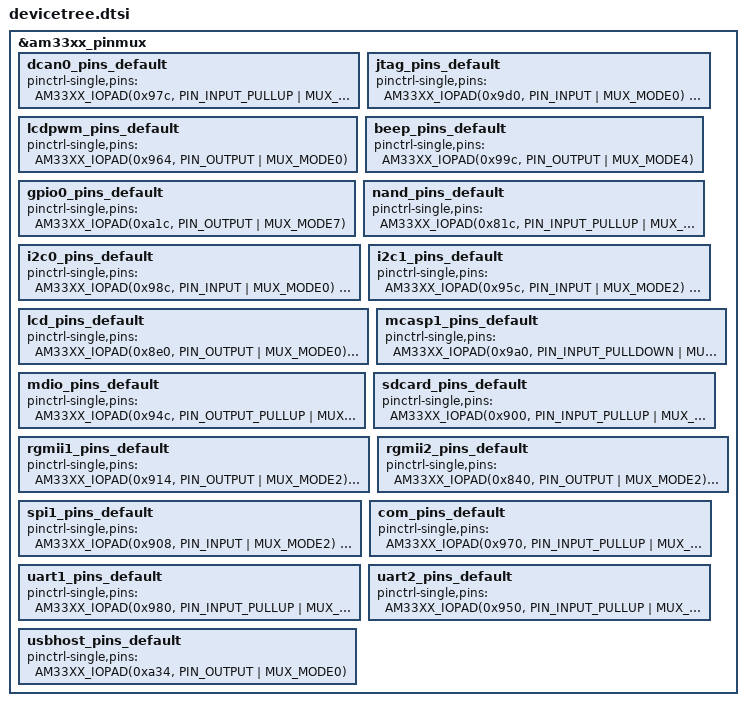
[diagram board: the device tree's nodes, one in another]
/* This file was auto-generated by TI PinMux on 2021/3/4 at 下午6:34:33. */
/* This file should only be used as a reference. Some pins/peripherals, */
/* depending on your use case, may need additional configuration. */

/* Some or all the pins from the following groups are not used by device tree 
   adc
   ddr3l
   otg
   usbhost
*/

&am33xx_pinmux {
	dcan0_pins_default: dcan0_pins_default {
		pinctrl-single,pins = <
			AM33XX_IOPAD(0x97c, PIN_INPUT_PULLUP | MUX_MODE2) /* (D17) uart1_rtsn.dcan0_rx */
			AM33XX_IOPAD(0x978, PIN_OUTPUT | MUX_MODE2) /* (D18) uart1_ctsn.dcan0_tx */
		>;
	};

	jtag_pins_default: jtag_pins_default {
		pinctrl-single,pins = <
			AM33XX_IOPAD(0x9d0, PIN_INPUT | MUX_MODE0) /* (C11) TMS.TMS */
			AM33XX_IOPAD(0x9d4, PIN_INPUT | MUX_MODE0) /* (B11) TDI.TDI */
			AM33XX_IOPAD(0x9d8, PIN_OUTPUT | MUX_MODE0) /* (A11) TDO.TDO */
			AM33XX_IOPAD(0x9dc, PIN_INPUT | MUX_MODE0) /* (A12) TCK.TCK */
			AM33XX_IOPAD(0x9e0, PIN_INPUT | MUX_MODE0) /* (B10) nTRST.nTRST */
			AM33XX_IOPAD(0x9e4, PIN_INPUT | MUX_MODE0) /* (C14) EMU0.EMU0 */
			AM33XX_IOPAD(0x9e8, PIN_INPUT | MUX_MODE0) /* (B14) EMU1.EMU1 */
		>;
	};

	lcdpwm_pins_default: lcdpwm_pins_default {
		pinctrl-single,pins = <
			AM33XX_IOPAD(0x964, PIN_OUTPUT | MUX_MODE0) /* (C18) eCAP0_in_PWM0_out.eCAP0_in_PWM0_out */
		>;
	};

	beep_pins_default: beep_pins_default {
		pinctrl-single,pins = <
			AM33XX_IOPAD(0x99c, PIN_OUTPUT | MUX_MODE4) /* (C12) mcasp0_ahclkr.eCAP2_in_PWM2_out */
		>;
	};

	gpio0_pins_default: gpio0_pins_default {
		pinctrl-single,pins = <
			AM33XX_IOPAD(0xa1c, PIN_OUTPUT | MUX_MODE7) /* (F16) USB0_DRVVBUS.gpio0[18] */
		>;
	};

	nand_pins_default: nand_pins_default {
		pinctrl-single,pins = <
			AM33XX_IOPAD(0x81c, PIN_INPUT_PULLUP | MUX_MODE0) /* (T9) gpmc_ad7.gpmc_ad7 */
			AM33XX_IOPAD(0x818, PIN_INPUT_PULLUP | MUX_MODE0) /* (R9) gpmc_ad6.gpmc_ad6 */
			AM33XX_IOPAD(0x814, PIN_INPUT_PULLUP | MUX_MODE0) /* (V8) gpmc_ad5.gpmc_ad5 */
			AM33XX_IOPAD(0x810, PIN_INPUT_PULLUP | MUX_MODE0) /* (U8) gpmc_ad4.gpmc_ad4 */
			AM33XX_IOPAD(0x80c, PIN_INPUT_PULLUP | MUX_MODE0) /* (T8) gpmc_ad3.gpmc_ad3 */
			AM33XX_IOPAD(0x808, PIN_INPUT_PULLUP | MUX_MODE0) /* (R8) gpmc_ad2.gpmc_ad2 */
			AM33XX_IOPAD(0x804, PIN_INPUT_PULLUP | MUX_MODE0) /* (V7) gpmc_ad1.gpmc_ad1 */
			AM33XX_IOPAD(0x800, PIN_INPUT_PULLUP | MUX_MODE0) /* (U7) gpmc_ad0.gpmc_ad0 */
			AM33XX_IOPAD(0x870, PIN_INPUT_PULLUP | MUX_MODE0) /* (T17) gpmc_wait0.gpmc_wait0 */
			AM33XX_IOPAD(0x87c, PIN_OUTPUT | MUX_MODE0) /* (V6) gpmc_csn0.gpmc_csn0 */
			AM33XX_IOPAD(0x890, PIN_OUTPUT | MUX_MODE0) /* (R7) gpmc_advn_ale.gpmc_advn_ale */
			AM33XX_IOPAD(0x894, PIN_OUTPUT | MUX_MODE0) /* (T7) gpmc_oen_ren.gpmc_oen_ren */
			AM33XX_IOPAD(0x898, PIN_OUTPUT | MUX_MODE0) /* (U6) gpmc_wen.gpmc_wen */
			AM33XX_IOPAD(0x89c, PIN_OUTPUT | MUX_MODE0) /* (T6) gpmc_be0n_cle.gpmc_be0n_cle */
		>;
	};

	i2c0_pins_default: i2c0_pins_default {
		pinctrl-single,pins = <
			AM33XX_IOPAD(0x98c, PIN_INPUT | MUX_MODE0) /* (C16) I2C0_SCL.I2C0_SCL */
			AM33XX_IOPAD(0x988, PIN_INPUT | MUX_MODE0) /* (C17) I2C0_SDA.I2C0_SDA */
		>;
	};

	i2c1_pins_default: i2c1_pins_default {
		pinctrl-single,pins = <
			AM33XX_IOPAD(0x95c, PIN_INPUT | MUX_MODE2) /* (A16) spi0_cs0.I2C1_SCL */
			AM33XX_IOPAD(0x958, PIN_INPUT | MUX_MODE2) /* (B16) spi0_d1.I2C1_SDA */
		>;
	};

	lcd_pins_default: lcd_pins_default {
		pinctrl-single,pins = <
			AM33XX_IOPAD(0x8e0, PIN_OUTPUT | MUX_MODE0) /* (U5) lcd_vsync.lcd_vsync */
			AM33XX_IOPAD(0x8e4, PIN_OUTPUT | MUX_MODE0) /* (R5) lcd_hsync.lcd_hsync */
			AM33XX_IOPAD(0x8e8, PIN_OUTPUT | MUX_MODE0) /* (V5) lcd_pclk.lcd_pclk */
			AM33XX_IOPAD(0x8ec, PIN_OUTPUT | MUX_MODE0) /* (R6) lcd_ac_bias_en.lcd_ac_bias_en */
			AM33XX_IOPAD(0x8a0, PIN_OUTPUT | MUX_MODE0) /* (R1) lcd_data0.lcd_data0 */
			AM33XX_IOPAD(0x8a4, PIN_OUTPUT | MUX_MODE0) /* (R2) lcd_data1.lcd_data1 */
			AM33XX_IOPAD(0x8a8, PIN_OUTPUT | MUX_MODE0) /* (R3) lcd_data2.lcd_data2 */
			AM33XX_IOPAD(0x8ac, PIN_OUTPUT | MUX_MODE0) /* (R4) lcd_data3.lcd_data3 */
			AM33XX_IOPAD(0x8b0, PIN_OUTPUT | MUX_MODE0) /* (T1) lcd_data4.lcd_data4 */
			AM33XX_IOPAD(0x8b4, PIN_OUTPUT | MUX_MODE0) /* (T2) lcd_data5.lcd_data5 */
			AM33XX_IOPAD(0x8b8, PIN_OUTPUT | MUX_MODE0) /* (T3) lcd_data6.lcd_data6 */
			AM33XX_IOPAD(0x8bc, PIN_OUTPUT | MUX_MODE0) /* (T4) lcd_data7.lcd_data7 */
			AM33XX_IOPAD(0x8c0, PIN_OUTPUT | MUX_MODE0) /* (U1) lcd_data8.lcd_data8 */
			AM33XX_IOPAD(0x8c4, PIN_OUTPUT | MUX_MODE0) /* (U2) lcd_data9.lcd_data9 */
			AM33XX_IOPAD(0x8c8, PIN_OUTPUT | MUX_MODE0) /* (U3) lcd_data10.lcd_data10 */
			AM33XX_IOPAD(0x8cc, PIN_OUTPUT | MUX_MODE0) /* (U4) lcd_data11.lcd_data11 */
			AM33XX_IOPAD(0x8d0, PIN_OUTPUT | MUX_MODE0) /* (V2) lcd_data12.lcd_data12 */
			AM33XX_IOPAD(0x8d4, PIN_OUTPUT | MUX_MODE0) /* (V3) lcd_data13.lcd_data13 */
			AM33XX_IOPAD(0x8d8, PIN_OUTPUT | MUX_MODE0) /* (V4) lcd_data14.lcd_data14 */
			AM33XX_IOPAD(0x8dc, PIN_OUTPUT | MUX_MODE0) /* (T5) lcd_data15.lcd_data15 */
			AM33XX_IOPAD(0x83c, PIN_OUTPUT | MUX_MODE1) /* (U13) gpmc_ad15.lcd_data16 */
			AM33XX_IOPAD(0x838, PIN_OUTPUT | MUX_MODE1) /* (V13) gpmc_ad14.lcd_data17 */
			AM33XX_IOPAD(0x834, PIN_OUTPUT | MUX_MODE1) /* (R12) gpmc_ad13.lcd_data18 */
			AM33XX_IOPAD(0x830, PIN_OUTPUT | MUX_MODE1) /* (T12) gpmc_ad12.lcd_data19 */
			AM33XX_IOPAD(0x82c, PIN_OUTPUT | MUX_MODE1) /* (U12) gpmc_ad11.lcd_data20 */
			AM33XX_IOPAD(0x828, PIN_OUTPUT | MUX_MODE1) /* (T11) gpmc_ad10.lcd_data21 */
			AM33XX_IOPAD(0x824, PIN_OUTPUT | MUX_MODE1) /* (T10) gpmc_ad9.lcd_data22 */
			AM33XX_IOPAD(0x820, PIN_OUTPUT | MUX_MODE1) /* (U10) gpmc_ad8.lcd_data23 */
		>;
	};

	mcasp1_pins_default: mcasp1_pins_default {
		pinctrl-single,pins = <
			AM33XX_IOPAD(0x9a0, PIN_INPUT_PULLDOWN | MUX_MODE3) /* (B12) mcasp0_aclkr.mcasp1_aclkx */
			AM33XX_IOPAD(0x9a4, PIN_INPUT_PULLDOWN | MUX_MODE3) /* (C13) mcasp0_fsr.mcasp1_fsx */
			AM33XX_IOPAD(0x9a8, PIN_OUTPUT_PULLDOWN | MUX_MODE3) /* (D13) mcasp0_axr1.mcasp1_axr0 */
			AM33XX_IOPAD(0x9ac, PIN_OUTPUT_PULLDOWN | MUX_MODE3) /* (A14) mcasp0_ahclkx.mcasp1_axr1 */
		>;
	};

	mdio_pins_default: mdio_pins_default {
		pinctrl-single,pins = <
			AM33XX_IOPAD(0x94c, PIN_OUTPUT_PULLUP | MUX_MODE0) /* (M18) mdio_clk.mdio_clk */
			AM33XX_IOPAD(0x948, PIN_INPUT_PULLUP | MUX_MODE0) /* (M17) mdio_data.mdio_data */
		>;
	};

	sdcard_pins_default: sdcard_pins_default {
		pinctrl-single,pins = <
			AM33XX_IOPAD(0x900, PIN_INPUT_PULLUP | MUX_MODE0) /* (G17) mmc0_clk.mmc0_clk */
			AM33XX_IOPAD(0x904, PIN_INPUT_PULLUP | MUX_MODE0) /* (G18) mmc0_cmd.mmc0_cmd */
			AM33XX_IOPAD(0x8fc, PIN_INPUT_PULLUP | MUX_MODE0) /* (G16) mmc0_dat0.mmc0_dat0 */
			AM33XX_IOPAD(0x8f8, PIN_INPUT_PULLUP | MUX_MODE0) /* (G15) mmc0_dat1.mmc0_dat1 */
			AM33XX_IOPAD(0x8f4, PIN_INPUT_PULLUP | MUX_MODE0) /* (F18) mmc0_dat2.mmc0_dat2 */
			AM33XX_IOPAD(0x8f0, PIN_INPUT_PULLUP | MUX_MODE0) /* (F17) mmc0_dat3.mmc0_dat3 */
			AM33XX_IOPAD(0x960, PIN_INPUT_PULLUP | MUX_MODE5) /* (C15) spi0_cs1.mmc0_sdcd */
		>;
	};

	rgmii1_pins_default: rgmii1_pins_default {
		pinctrl-single,pins = <
			AM33XX_IOPAD(0x914, PIN_OUTPUT | MUX_MODE2) /* (J16) gmii1_txen.rgmii1_tctl */
			AM33XX_IOPAD(0x918, PIN_INPUT_PULLDOWN | MUX_MODE2) /* (J17) gmii1_rxdv.rgmii1_rctl */
			AM33XX_IOPAD(0x92c, PIN_OUTPUT | MUX_MODE2) /* (K18) gmii1_txclk.rgmii1_tclk */
			AM33XX_IOPAD(0x930, PIN_INPUT_PULLDOWN | MUX_MODE2) /* (L18) gmii1_rxclk.rgmii1_rclk */
			AM33XX_IOPAD(0x928, PIN_OUTPUT | MUX_MODE2) /* (K17) gmii1_txd0.rgmii1_td0 */
			AM33XX_IOPAD(0x924, PIN_OUTPUT | MUX_MODE2) /* (K16) gmii1_txd1.rgmii1_td1 */
			AM33XX_IOPAD(0x920, PIN_OUTPUT | MUX_MODE2) /* (K15) gmii1_txd2.rgmii1_td2 */
			AM33XX_IOPAD(0x91c, PIN_OUTPUT | MUX_MODE2) /* (J18) gmii1_txd3.rgmii1_td3 */
			AM33XX_IOPAD(0x940, PIN_INPUT_PULLDOWN | MUX_MODE2) /* (M16) gmii1_rxd0.rgmii1_rd0 */
			AM33XX_IOPAD(0x93c, PIN_INPUT_PULLDOWN | MUX_MODE2) /* (L15) gmii1_rxd1.rgmii1_rd1 */
			AM33XX_IOPAD(0x938, PIN_INPUT_PULLDOWN | MUX_MODE2) /* (L16) gmii1_rxd2.rgmii1_rd2 */
			AM33XX_IOPAD(0x934, PIN_INPUT_PULLDOWN | MUX_MODE2) /* (L17) gmii1_rxd3.rgmii1_rd3 */
		>;
	};

	rgmii2_pins_default: rgmii2_pins_default {
		pinctrl-single,pins = <
			AM33XX_IOPAD(0x840, PIN_OUTPUT | MUX_MODE2) /* (R13) gpmc_a0.rgmii2_tctl */
			AM33XX_IOPAD(0x844, PIN_INPUT_PULLDOWN | MUX_MODE2) /* (V14) gpmc_a1.rgmii2_rctl */
			AM33XX_IOPAD(0x858, PIN_OUTPUT | MUX_MODE2) /* (U15) gpmc_a6.rgmii2_tclk */
			AM33XX_IOPAD(0x85c, PIN_INPUT_PULLDOWN | MUX_MODE2) /* (T15) gpmc_a7.rgmii2_rclk */
			AM33XX_IOPAD(0x854, PIN_OUTPUT | MUX_MODE2) /* (V15) gpmc_a5.rgmii2_td0 */
			AM33XX_IOPAD(0x850, PIN_OUTPUT | MUX_MODE2) /* (R14) gpmc_a4.rgmii2_td1 */
			AM33XX_IOPAD(0x84c, PIN_OUTPUT | MUX_MODE2) /* (T14) gpmc_a3.rgmii2_td2 */
			AM33XX_IOPAD(0x848, PIN_OUTPUT | MUX_MODE2) /* (U14) gpmc_a2.rgmii2_td3 */
			AM33XX_IOPAD(0x86c, PIN_INPUT_PULLDOWN | MUX_MODE2) /* (V17) gpmc_a11.rgmii2_rd0 */
			AM33XX_IOPAD(0x868, PIN_INPUT_PULLDOWN | MUX_MODE2) /* (T16) gpmc_a10.rgmii2_rd1 */
			AM33XX_IOPAD(0x864, PIN_INPUT_PULLDOWN | MUX_MODE2) /* (U16) gpmc_a9.rgmii2_rd2 */
			AM33XX_IOPAD(0x860, PIN_INPUT_PULLDOWN | MUX_MODE2) /* (V16) gpmc_a8.rgmii2_rd3 */
		>;
	};

	spi1_pins_default: spi1_pins_default {
		pinctrl-single,pins = <
			AM33XX_IOPAD(0x908, PIN_INPUT | MUX_MODE2) /* (H16) gmii1_col.spi1_sclk */
			AM33XX_IOPAD(0x90c, PIN_INPUT_PULLUP | MUX_MODE2) /* (H17) gmii1_crs.spi1_d0 */
			AM33XX_IOPAD(0x910, PIN_INPUT | MUX_MODE2) /* (J15) gmii1_rxer.spi1_d1 */
			AM33XX_IOPAD(0x944, PIN_INPUT_PULLUP | MUX_MODE2) /* (H18) rmii1_refclk.spi1_cs0 */
		>;
	};

	com_pins_default: com_pins_default {
		pinctrl-single,pins = <
			AM33XX_IOPAD(0x970, PIN_INPUT_PULLUP | MUX_MODE0) /* (E15) uart0_rxd.uart0_rxd */
			AM33XX_IOPAD(0x974, PIN_OUTPUT | MUX_MODE0) /* (E16) uart0_txd.uart0_txd */
		>;
	};

	uart1_pins_default: uart1_pins_default {
		pinctrl-single,pins = <
			AM33XX_IOPAD(0x980, PIN_INPUT_PULLUP | MUX_MODE0) /* (D16) uart1_rxd.uart1_rxd */
			AM33XX_IOPAD(0x984, PIN_OUTPUT | MUX_MODE0) /* (D15) uart1_txd.uart1_txd */
		>;
	};

	uart2_pins_default: uart2_pins_default {
		pinctrl-single,pins = <
			AM33XX_IOPAD(0x950, PIN_INPUT_PULLUP | MUX_MODE1) /* (A17) spi0_sclk.uart2_rxd */
			AM33XX_IOPAD(0x954, PIN_OUTPUT | MUX_MODE1) /* (B17) spi0_d0.uart2_txd */
		>;
	};

	usbhost_pins_default: usbhost_pins_default {
		pinctrl-single,pins = <
			AM33XX_IOPAD(0xa34, PIN_OUTPUT | MUX_MODE0) /* (F15) USB1_DRVVBUS.USB1_DRVVBUS */
		>;
	};

};
